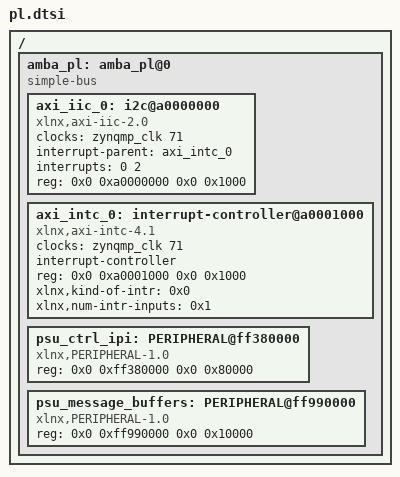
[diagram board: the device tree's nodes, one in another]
/*
 * CAUTION: This file is automatically generated by Xilinx.
 * Version: XSCT 2019.1
 * Today is: Wed Feb 17 22:50:54 2021
 */


/ {
	amba_pl: amba_pl@0 {
		#address-cells = <2>;
		#size-cells = <2>;
		compatible = "simple-bus";
		ranges ;
		axi_iic_0: i2c@a0000000 {
			#address-cells = <1>;
			#size-cells = <0>;
			clock-names = "s_axi_aclk";
			clocks = <&zynqmp_clk 71>;
			compatible = "xlnx,axi-iic-2.0", "xlnx,xps-iic-2.00.a";
			interrupt-names = "iic2intc_irpt";
			interrupt-parent = <&axi_intc_0>;
			interrupts = <0 2>;
			reg = <0x0 0xa0000000 0x0 0x1000>;
		};
		axi_intc_0: interrupt-controller@a0001000 {
			#interrupt-cells = <2>;
			clock-names = "s_axi_aclk";
			clocks = <&zynqmp_clk 71>;
			compatible = "xlnx,axi-intc-4.1", "xlnx,xps-intc-1.00.a";
			interrupt-controller ;
			reg = <0x0 0xa0001000 0x0 0x1000>;
			xlnx,kind-of-intr = <0x0>;
			xlnx,num-intr-inputs = <0x1>;
		};
		psu_ctrl_ipi: PERIPHERAL@ff380000 {
			/* This is a place holder node for a custom IP, user may need to update the entries */
			compatible = "xlnx,PERIPHERAL-1.0";
			reg = <0x0 0xff380000 0x0 0x80000>;
		};
		psu_message_buffers: PERIPHERAL@ff990000 {
			/* This is a place holder node for a custom IP, user may need to update the entries */
			compatible = "xlnx,PERIPHERAL-1.0";
			reg = <0x0 0xff990000 0x0 0x10000>;
		};
	};
};
